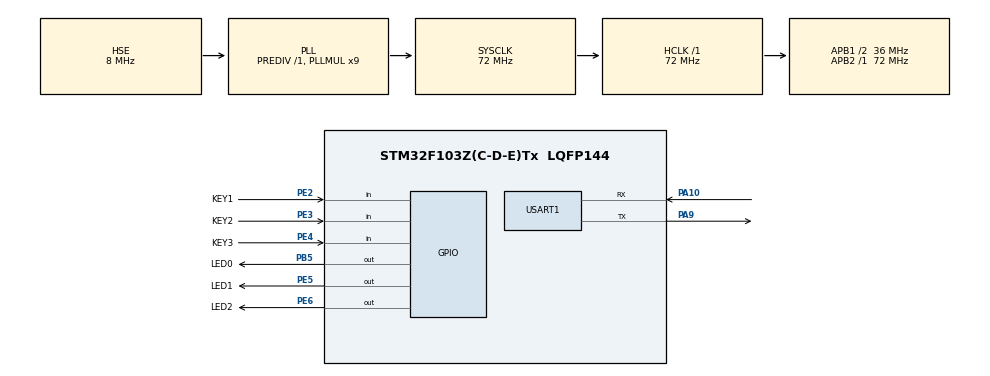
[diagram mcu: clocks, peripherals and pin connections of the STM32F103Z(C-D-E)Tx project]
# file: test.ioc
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Dma.Request0=USART1_RX
Dma.Request1=USART1_TX
Dma.USART1_RX.0.Direction=DMA_PERIPH_TO_MEMORY
Dma.USART1_RX.0.Instance=DMA1_Channel5
Dma.USART1_RX.0.MemDataAlignment=DMA_MDATAALIGN_BYTE
Dma.USART1_RX.0.MemInc=DMA_MINC_ENABLE
Dma.USART1_RX.0.Mode=DMA_NORMAL
Dma.USART1_RX.0.PeriphDataAlignment=DMA_PDATAALIGN_BYTE
Dma.USART1_RX.0.PeriphInc=DMA_PINC_DISABLE
Dma.USART1_RX.0.Priority=DMA_PRIORITY_MEDIUM
Dma.USART1_TX.1.Direction=DMA_MEMORY_TO_PERIPH
Dma.USART1_TX.1.Instance=DMA1_Channel4
Dma.USART1_TX.1.MemDataAlignment=DMA_MDATAALIGN_BYTE
Dma.USART1_TX.1.MemInc=DMA_MINC_ENABLE
Dma.USART1_TX.1.Mode=DMA_NORMAL
Dma.USART1_TX.1.PeriphDataAlignment=DMA_PDATAALIGN_BYTE
Dma.USART1_TX.1.PeriphInc=DMA_PINC_DISABLE
Dma.USART1_TX.1.Priority=DMA_PRIORITY_LOW
Mcu.Family=STM32F1
Mcu.Name=STM32F103Z(C-D-E)Tx
Mcu.Package=LQFP144
NVIC.DMA1_Channel4_IRQn=true\:2\:0\:true\:false\:true\:false\:true
NVIC.DMA1_Channel5_IRQn=true\:3\:0\:true\:false\:true\:false\:true
NVIC.PriorityGroup=NVIC_PRIORITYGROUP_4
NVIC.USART1_IRQn=true\:1\:0\:true\:false\:true\:true\:true
OSC_IN.Mode=HSE-External-Oscillator
OSC_IN.Signal=RCC_OSC_IN
OSC_OUT.Mode=HSE-External-Oscillator
OSC_OUT.Signal=RCC_OSC_OUT
PA0-WKUP.Mode=SYS_WakeUp0
PA0-WKUP.Signal=SYS_WKUP
PA10.Mode=Asynchronous
PA10.Signal=USART1_RX
PA13.Mode=JTAG_5_pins
PA13.Signal=SYS_JTMS-SWDIO
PA14.Mode=JTAG_5_pins
PA14.Signal=SYS_JTCK-SWCLK
PA15.Mode=JTAG_5_pins
PA15.Signal=SYS_JTDI
PA9.Mode=Asynchronous
PA9.Signal=USART1_TX
PB3.Mode=JTAG_5_pins
PB3.Signal=SYS_JTDO-TRACESWO
PB4.Mode=JTAG_5_pins
PB4.Signal=SYS_NJTRST
PB5.GPIO_Label=LED0
PB5.PinState=GPIO_PIN_SET
PB5.Signal=GPIO_Output
PC14-OSC32_IN.Mode=LSE-External-Oscillator
PC14-OSC32_IN.Signal=RCC_OSC32_IN
PC15-OSC32_OUT.Mode=LSE-External-Oscillator
PC15-OSC32_OUT.Signal=RCC_OSC32_OUT
PE2.GPIO_Label=KEY1
PE2.Signal=GPIO_Input
PE3.GPIO_Label=KEY2
PE3.Signal=GPIO_Input
PE4.GPIO_Label=KEY3
PE4.Signal=GPIO_Input
PE5.GPIO_Label=LED1
PE5.PinState=GPIO_PIN_SET
PE5.Signal=GPIO_Output
PE6.GPIO_Label=LED2
PE6.Signal=GPIO_Output
ProjectManager.HeapSize=0x800
ProjectManager.StackSize=0x1000
ProjectManager.TargetToolchain=MDK-ARM V5.27
RCC.AHBFreq_Value=72000000
RCC.APB1CLKDivider=RCC_HCLK_DIV2
RCC.APB1Freq_Value=36000000
RCC.APB1TimFreq_Value=72000000
RCC.APB2Freq_Value=72000000
RCC.APB2TimFreq_Value=72000000
RCC.HCLKFreq_Value=72000000
RCC.PLLMUL=RCC_PLL_MUL9
RCC.PLLSourceVirtual=RCC_PLLSOURCE_HSE
RCC.RTCClockSelection=RCC_RTCCLKSOURCE_LSE
RCC.SYSCLKFreq_VALUE=72000000
RCC.SYSCLKSource=RCC_SYSCLKSOURCE_PLLCLK
RCC.USBFreq_Value=48000000
RCC.USBPrescaler=RCC_USBCLKSOURCE_PLL_DIV1_5
RTC.Date=10
RTC.Format=RTC_FORMAT_BCD
RTC.Hours=11
RTC.Minutes=15
RTC.Month=RTC_MONTH_DECEMBER
RTC.WeekDay=RTC_WEEKDAY_TUESDAY
RTC.Year=19
USART1.VirtualMode=VM_ASYNC
VP_RTC_VS_RTC_Activate.Mode=RTC_Enabled
VP_RTC_VS_RTC_Calendar.Mode=RTC_Calendar
board=custom

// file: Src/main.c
/* USER CODE BEGIN Header */
/**
  ******************************************************************************
  * @file           : main.c
  * @brief          : Main program body
  ******************************************************************************
  * @attention
  *
  * <h2><center>&copy; Copyright (c) 2020 STMicroelectronics.
  * All rights reserved.</center></h2>
  *
  * This software component is licensed by ST under Ultimate Liberty license
  * SLA0044, the "License"; You may not use this file except in compliance with
  * the License. You may obtain a copy of the License at:
  *                             www.st.com/SLA0044
  *
  ******************************************************************************
  */
/* USER CODE END Header */

#include "main.h"
#include "dma.h"
#include "rtc.h"
#include "usart.h"
#include "gpio.h"

/* USER CODE BEGIN PD */
#define NVIC_VectTab_FLASH           ((uint32_t)0x08000000)
#define VectorTable_Offset          0x9000  //需要和MDK的Target选项卡，IROM1的Start一致，否则出错
/* USER CODE END PD */

void SystemClock_Config(void);
/* USER CODE BEGIN PFP */
void Nvic_SetVectorTable(uint32_t NVIC_VectTab, uint32_t Offset);
/* USER CODE END PFP */

int main(void)
{

  /* MCU Configuration--------------------------------------------------------*/

  /* Reset of all peripherals, Initializes the Flash interface and the Systick. */
  HAL_Init();

  /* Configure the system clock */
  SystemClock_Config();

  /* USER CODE BEGIN SysInit */
    Nvic_SetVectorTable(NVIC_VectTab_FLASH, VectorTable_Offset);
  /* USER CODE END SysInit */

  /* Initialize all configured peripherals */
  MX_GPIO_Init();
  MX_DMA_Init();
  MX_USART1_UART_Init();
  MX_RTC_Init();

  /* Infinite loop */
  /* USER CODE BEGIN WHILE */

  while (1)
  {
      HAL_GPIO_WritePin(LED2_GPIO_Port, LED2_Pin, GPIO_PIN_SET);
      HAL_Delay(500);
      HAL_GPIO_WritePin(LED2_GPIO_Port, LED2_Pin, GPIO_PIN_RESET);
      HAL_Delay(500);

      if (HAL_GPIO_ReadPin(KEY2_GPIO_Port, KEY2_Pin) == GPIO_PIN_RESET)
      {
          HAL_NVIC_SystemReset();   //回到BootLoader中,从RAM地址0x00000000处开始启动
      }
    /* USER CODE END WHILE */

  }
}

void SystemClock_Config(void)
{
  RCC_OscInitTypeDef RCC_OscInitStruct = {0};
  RCC_ClkInitTypeDef RCC_ClkInitStruct = {0};
  RCC_PeriphCLKInitTypeDef PeriphClkInit = {0};

  /** Initializes the CPU, AHB and APB busses clocks
  */
  RCC_OscInitStruct.OscillatorType = RCC_OSCILLATORTYPE_HSE|RCC_OSCILLATORTYPE_LSE;
  RCC_OscInitStruct.HSEState = RCC_HSE_ON;
  RCC_OscInitStruct.HSEPredivValue = RCC_HSE_PREDIV_DIV1;
  RCC_OscInitStruct.LSEState = RCC_LSE_ON;
  RCC_OscInitStruct.HSIState = RCC_HSI_ON;
  RCC_OscInitStruct.PLL.PLLState = RCC_PLL_ON;
  RCC_OscInitStruct.PLL.PLLSource = RCC_PLLSOURCE_HSE;
  RCC_OscInitStruct.PLL.PLLMUL = RCC_PLL_MUL9;
  if (HAL_RCC_OscConfig(&RCC_OscInitStruct) != HAL_OK)
  {
    Error_Handler();
  }
  /** Initializes the CPU, AHB and APB busses clocks
  */
  RCC_ClkInitStruct.ClockType = RCC_CLOCKTYPE_HCLK|RCC_CLOCKTYPE_SYSCLK
                              |RCC_CLOCKTYPE_PCLK1|RCC_CLOCKTYPE_PCLK2;
  RCC_ClkInitStruct.SYSCLKSource = RCC_SYSCLKSOURCE_PLLCLK;
  RCC_ClkInitStruct.AHBCLKDivider = RCC_SYSCLK_DIV1;
  RCC_ClkInitStruct.APB1CLKDivider = RCC_HCLK_DIV2;
  RCC_ClkInitStruct.APB2CLKDivider = RCC_HCLK_DIV1;

  if (HAL_RCC_ClockConfig(&RCC_ClkInitStruct, FLASH_LATENCY_2) != HAL_OK)
  {
    Error_Handler();
  }
  PeriphClkInit.PeriphClockSelection = RCC_PERIPHCLK_RTC;
  PeriphClkInit.RTCClockSelection = RCC_RTCCLKSOURCE_LSE;
  if (HAL_RCCEx_PeriphCLKConfig(&PeriphClkInit) != HAL_OK)
  {
    Error_Handler();
  }
}

/* USER CODE BEGIN 4 */
void Nvic_SetVectorTable(uint32_t NVIC_VectTab, uint32_t Offset)
{
    SCB->VTOR = NVIC_VectTab|(Offset & (uint32_t)0x1FFFFF80);//设置NVIC的向量表偏移寄存器
}
/* USER CODE END 4 */

void Error_Handler(void)
{
}

/************************ (C) COPYRIGHT STMicroelectronics *****END OF FILE****/
